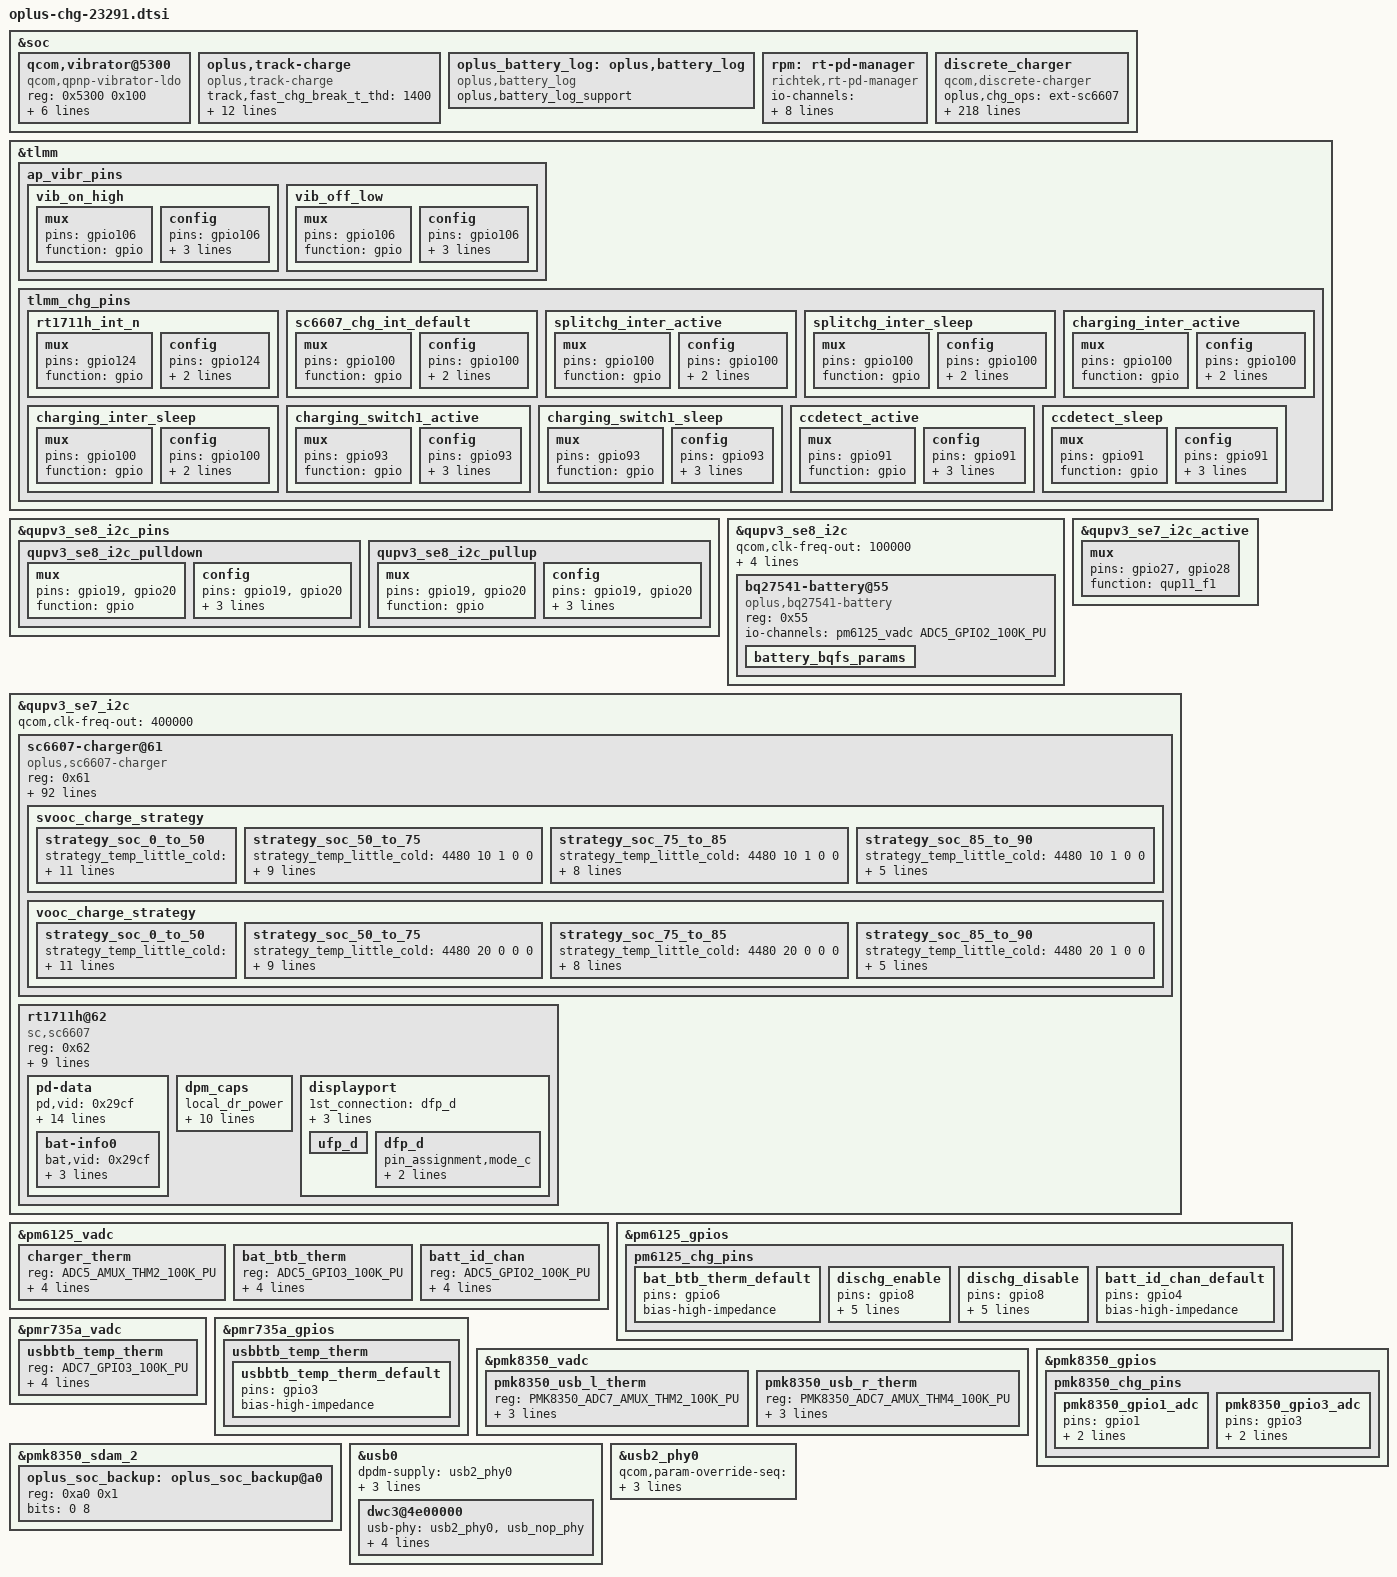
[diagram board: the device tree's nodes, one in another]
#include <dt-bindings/spmi/spmi.h>
#include <dt-bindings/iio/qcom,spmi-vadc.h>
#include <dt-bindings/iio/qti_power_supply_iio.h>

&soc {
	qcom,vibrator@5300 {
		compatible = "qcom,qpnp-vibrator-ldo";
		reg = <0x5300 0x100>;
		qcom,vib-ldo-volt-uv = <3000000>;
		qcom,disable-overdrive;
		qcom,vib-type = <1>;	/*0:ldo 1:gpio*/
		status = "okay";

		qcom,vibrator_switch-gpio = <&tlmm 106 0x00>;
		pinctrl-names = "vib_on_high", "vib_off_low";
		pinctrl-0 = <&vib_on_high>;
		pinctrl-1 = <&vib_off_low >;
	};

	oplus,track-charge {
		compatible = "oplus,track-charge";
		track,fast_chg_break_t_thd = <1400>;
		track,general_chg_break_t_thd = <200>;
		track,voocphy_type = <3>;
		track,wired_max_power = <67000>;
		track,wired_fast_chg_scheme = <2>;
		track,wls_max_power = <0>;
		track,wls_bpp_chg_scheme = <0>;
		track,wls_epp_chg_scheme = <0>;
		track,wls_fast_chg_scheme = <0>;
		track,nominal_qmax1 = <4824>;
		track,nominal_fcc = <4510>;
		track,gauge_status_ctrl;
		track,external_gauge_num = <1>;
	};

	oplus_battery_log: oplus,battery_log {
		compatible = "oplus,battery_log";
		oplus,battery_log_support;
	};
};

&tlmm {
	ap_vibr_pins {
		vib_on_high {
			mux {
				pins = "gpio106";
				function = "gpio";
			};

			config {
				pins = "gpio106";
				drive-strength = <2>;
				bias-disable;
				output-high;
			};
		};

		vib_off_low {
			mux {
				pins = "gpio106";
				function = "gpio";
			};

			config {
				pins = "gpio106";
				drive-strength = <2>;
				bias-disable;
				output-low;
			};
		};
	};
};

&qupv3_se8_i2c_pins {
	qupv3_se8_i2c_pulldown: qupv3_se8_i2c_pulldown {
		mux {
			pins = "gpio19", "gpio20";
			function = "gpio";
		};

		config {
			pins = "gpio19", "gpio20";
			drive-strength = <2>;
			bias-pull-down;
			output-low;
		};
	};

	qupv3_se8_i2c_pullup: qupv3_se8_i2c_pullup {
		mux {
			pins = "gpio19", "gpio20";
			function = "gpio";
		};

		config {
			pins = "gpio19", "gpio20";
			drive-strength = <2>;
			bias-pull-up;
			input-enable;
		};
	};
};

&qupv3_se8_i2c {
	status = "okay";
	qcom,clk-freq-out = <100000>;
	pinctrl-names = "default", "sleep", "pulldown", "pullup";
	pinctrl-0 = <&qupv3_se8_i2c_active>;
	pinctrl-1 = <&qupv3_se8_i2c_sleep>;
	pinctrl-2 = <&qupv3_se8_i2c_pulldown>;
	pinctrl-3 = <&qupv3_se8_i2c_pullup>;

	bq27541-battery@55 {
		status = "okay";
		compatible = "oplus,bq27541-battery";
		reg = <0x55>;
		io-channels = <&pm6125_vadc ADC5_GPIO2_100K_PU>;
		io-channel-names = "batt_id_chan";
		battery_bqfs_params {
			#include "oplus-bqfs-23091.dtsi"
		};
	};

};

&soc {
	rpm: rt-pd-manager {
		compatible = "richtek,rt-pd-manager";
		#io-channel-cells = <1>;
		io-channels = <&discrete_charger PSY_IIO_PD_ACTIVE>,
			      <&discrete_charger PSY_IIO_PD_USB_SUSPEND_SUPPORTED>,
			      <&discrete_charger PSY_IIO_PD_IN_HARD_RESET>,
			      <&discrete_charger PSY_IIO_PD_CURRENT_MAX>,
			      <&discrete_charger PSY_IIO_PD_VOLTAGE_MIN>,
			      <&discrete_charger PSY_IIO_PD_VOLTAGE_MAX>,
			      <&discrete_charger PSY_IIO_USB_REAL_TYPE>,
			      <&discrete_charger PSY_IIO_PD_SDP>;
		io-channel-names = "pd_active",
				   "pd_usb_suspend_supported",
				   "pd_in_hard_reset",
				   "pd_current_max",
				   "pd_voltage_min",
				   "pd_voltage_max",
				   "real_type",
				   "pd_sdp";
	};
};

&qupv3_se7_i2c_active {
	mux {
		pins = "gpio27", "gpio28";
		function = "qup11_f1";
	};
};

/*#ifdef OPLUS_FEATURE_CHG_BASIC*/
&qupv3_se7_i2c {
	status = "okay";
	qcom,clk-freq-out = <400000>;
	sc6607-charger@61 {
		status = "okay";
		compatible = "oplus,sc6607-charger";
		reg = <0x61>; /*The device operates as a slave device with address 75H*/

		qcom,chg_irq_gpio = <&tlmm 100 0x00>;
		dpdm-supply = <&usb2_phy0>;
		pinctrl-names = "default",
					"splitchg_inter_active",
					"splitchg_inter_sleep";

		pinctrl-0 = <&sc6607_chg_int_default>;
		pinctrl-1 = <&splitchg_inter_active>;
		pinctrl-2 = <&splitchg_inter_sleep>;

		sc,vsys-limit = <3400>;
		sc,vbat = <4450>;
		sc,charge-curr = <2000>;
		sc,iindpm-disable = <0>;
		sc,input-curr-limit = <500>;
		sc,ico-enable = <0>;
		sc,precharge-volt = <0>;      /* 0:2700mv , 1:3000mv */
		sc,precharge-curr = <500>;
		sc,term-en = <1>;
		sc,term-curr = <100>;     /* ma */
		sc,rechg-dis = <1>;
		sc,boost-voltage = <5000>;
		sc,boost-max-current = <1500>;
		sc,conv-ocp-dis = <0>;
		sc,tsbat-jeita-dis = <1>;
		sc,vpmid-ovp-otg-dis = <0>;
		sc,vbat-ovp-buck-dis = <0>;
		sc,ibat-ocp = <1>;    /* 0:12A , 1:16A */
		sc,charge-detect-enable;
		sc,disable-qc;
		qcom,copycat_vooc_support;
		oplus,copycat_identify_algorithm = <2>;
		oplus,copycat-vooc-count = <4>;

		/*
		 * Charger name
		 * Main charger: primary_chg
		 * Slave charger: secondary_chg
		 */
		charger_name = "primary_chg";

		qcom,mb_gauge_support;
		qcom,charging_switch1-gpio = <&tlmm 93 0x00>;

		ovp_reg = <0x36>;   /* 4850mv*/
		ocp_reg = <0xf>;    /* 4750mA*/

		qcom,voocphy_current_default = <41>;/*4100mA*/

		qcom,svooc_cool_down_current_limit = <82 20 20 24 30 34 40 44 50 54 82>;
		qcom,vooc_cool_down_current_limit = <30 20 20 24 30>;
		qcom,abnormal_adapter_current = <60 60 40 40>;
		qcom,vooc_little_cold_full_voltage = <4470>;
		qcom,vooc_cool_full_voltage = <4480>;
		qcom,vooc_warm_full_voltage = <4130>;
		qcom,vooc_1time_full_voltage = <4530>;
		qcom,vooc_ntime_full_voltage = <4520>;
		qcom,low_curr_full_t1 = <120>;
		qcom,low_curr_full_t2 = <350>;
		qcom,low_curr_full_t3 = <430>;
		qcom,range1_low_curr_full =	<850 4520
						  750 4515
						  650 4500
						  550 4490
						  450 4480>;
		qcom,range2_low_curr_full =	<900 4520
						 800 4515
						 700 4500
						 600 4490
						 500 4480>;

		qcom,vooc_multistep_initial_batt_temp = <1000>;
		qcom,vooc_little_cool_temp = <200>;
		qcom,vooc_cool_temp = <120>;
		qcom,vooc_little_cold_temp = <50>;
		qcom,vooc_normal_low_temp = <350>;
		qcom,vooc_strategy_normal_current = <100>;
		qcom,vooc_normal_to_little_cool_current = <100>;
		qcom,vooc_batt_over_high_temp = <510>;
		qcom,vooc-low-temp = <0>;
		qcom,vooc-high-temp = <500>;
		qcom,vooc-low-soc = <0>;
		qcom,vooc-high-soc = <90>;
		qcom,vooc-normal-high-temp = <430>;
		qcom,vooc-warm-allow-vol = <4000>;
		qcom,vooc-warm-allow-soc = <50>;

		qcom,vooc_strategy1_batt_high_temp0 = <385>;
		qcom,vooc_strategy1_batt_high_temp1 = <395>;
		qcom,vooc_strategy1_batt_high_temp2 = <420>;
		qcom,vooc_strategy1_batt_low_temp2 = <410>;
		qcom,vooc_strategy1_batt_low_temp1 = <385>;
		qcom,vooc_strategy1_batt_low_temp0 = <375>;

		qcom,vooc_strategy1_high_current0 = <80>;
		qcom,vooc_strategy1_high_current1 = <60>;
		qcom,vooc_strategy1_high_current2 = <40>;
		qcom,vooc_strategy1_low_current2 = <60>;
		qcom,vooc_strategy1_low_current1 = <80>;
		qcom,vooc_strategy1_low_current0 = <80>;

		qcom,vooc_strategy1_high_current0_vooc = <30>;
		qcom,vooc_strategy1_high_current1_vooc = <30>;
		qcom,vooc_strategy1_high_current2_vooc = <30>;
		qcom,vooc_strategy1_low_current2_vooc = <30>;
		qcom,vooc_strategy1_low_current1_vooc = <30>;
		qcom,vooc_strategy1_low_current0_vooc = <30>;

		qcom,voocphy_ibat_over_current = <8500>;
		qcom,voocphy_cp_max_ibus = <4750>;
		qcom,voocphy_svooc_cp_max_ibus = <4750>;
		qcom,voocphy_vooc_cp_max_ibus = <3500>;

		svooc_batt_sys_curve =	<0 1 0 1 0 0 1	// 4000mA
					 0 0 0 0 0 0 1	// 4604mV
					 0 0 1 0 1 0 0	// 2600mA
					 1 1 1 1 1 1 0	// 4604mV
					 0 0 0 1 0 1 0	// 1100mA
					 1 1 1 1 1 1 0>; // 4604mV

		vooc_batt_sys_curve =	<0 0 1 1 1 1 0	// 4000mA
					 0 0 0 0 0 0 1	// 4604mV
					 0 0 1 0 1 0 0	// 2600mA
					 1 1 1 1 1 1 0	// 4604mV
					 0 0 0 1 0 1 0	// 1100mA
					 1 1 1 1 1 1 0>; // 4604mV

	        svooc_charge_strategy {
	            strategy_soc_0_to_50 {
	                strategy_temp_little_cold =    <4150 15 0 0 0
	                                                4470 11 0 0 0
	                                                4480 10 1 0 0>;
	                strategy_temp_cool =           <4150 23 0 0 0
	                                                4150 20 0 0 0
	                                                4470 16 0 0 0
	                                                4470 15 0 0 0
	                                                4480 10 1 0 0>;
	                strategy_temp_little_cool =    <4150 35 0 0 0
	                                                4150 30 0 0 0
	                                                4480 28 0 0 0
	                                                4480 25 0 0 0
	                                                4480 20 0 0 0
	                                                4510 18 0 0 0
	                                                4510 15 0 0 0
	                                                4520 10 1 0 0>;
	                strategy_temp_normal_low =     <4230 41 0 0 0
	                                                4230 40 0 0 0
	                                                4230 35 0 0 0
	                                                4230 30 0 0 0
	                                                4480 28 0 0 0
	                                                4480 25 0 0 0
	                                                4480 20 0 0 0
	                                                4510 18 0 0 0
							4510 15 0 0 0
	                                                4520 10 1 0 0>;
	                strategy_temp_normal_high =    <4230 41 0 0 0
							4230 40 0 0 0
							4230 35 0 0 0
							4230 30 0 0 0
							4480 28 0 0 0
							4480 25 0 0 0
							4480 20 0 0 0
							4510 18 0 0 0
							4510 15 0 0 0
							4520 10 1 0 0>;
	                strategy_temp_warm =           <4120 13 0 0 0
							4130 10 1 0 0>;
	            };

	            strategy_soc_50_to_75 {
	                strategy_temp_little_cold =    <4480 10 1 0 0>;
	                strategy_temp_cool =           <4470 15 0 0 0
	                                                4480 10 1 0 0>;
	                strategy_temp_little_cool =    <4480 20 0 0 0
	                                                4510 18 0 0 0
							4510 15 0 0 0
	                                                4520 10 1 0 0>;
	                strategy_temp_normal_low =     <4480 25 0 0 0
	                                                4480 20 0 0 0
							4510 18 0 0 0
							4510 15 0 0 0
	                                                4520 10 1 0 0>;
	                strategy_temp_normal_high =    <4480 25 0 0 0
							4480 20 0 0 0
							4510 18 0 0 0
							4510 15 0 0 0
	                                                4520 10 1 0 0>;
	                strategy_temp_warm =           <4130 10 1 0 0>;
	            };

	            strategy_soc_75_to_85 {
	                strategy_temp_little_cold =    <4480 10 1 0 0>;
	                strategy_temp_cool =           <4480 20 0 0 0>;
	                strategy_temp_little_cool =    <4510 15 0 0 0
	                                                4520 10 1 0 0>;
	                strategy_temp_normal_low =     <4510 15 0 0 0
	                                                4520 10 1 0 0>;
	                strategy_temp_normal_high =    <4510 15 0 0 0
	                                                4520 10 1 0 0>;
	                strategy_temp_warm =           <4130 10 1 0 0>;
	            };

	            strategy_soc_85_to_90 {
	                strategy_temp_little_cold =    <4480 10 1 0 0>;
	                strategy_temp_cool =           <4480 10 1 0 0>;
	                strategy_temp_little_cool =    <4520 10 1 0 0>;
	                strategy_temp_normal_low =     <4520 10 1 0 0>;
	                strategy_temp_normal_high =    <4520 10 1 0 0>;
	                strategy_temp_warm =           <4130 10 1 0 0>;
	            };
	        };

	        vooc_charge_strategy {
	            strategy_soc_0_to_50 {
	                strategy_temp_little_cold =    <4150 30 0 0 0
	                                                4470 22 0 0 0
	                                                4480 20 1 0 0>;
	                strategy_temp_cool =           <4470 30 0 0 0
	                                                4480 20 1 0 0>;
	                strategy_temp_little_cool =    <4510 30 0 0 0
	                                                4520 20 1 0 0>;
	                strategy_temp_normal_low =     <4510 30 0 0 0
	                                                4520 20 1 0 0>;
	                strategy_temp_normal_high =    <4510 30 0 0 0
	                                                4520 20 1 0 0>;
	                strategy_temp_warm =           <4120 26 1 0 0
							4130 20 1 0 0>;
	            };

	            strategy_soc_50_to_75 {
	                strategy_temp_little_cold =    <4480 20 0 0 0>;
	                strategy_temp_cool =           <4470 30 0 0 0
	                                                4480 20 1 0 0>;
	                strategy_temp_little_cool =    <4510 30 0 0 0
	                                                4520 20 1 0 0>;
	                strategy_temp_normal_low =     <4510 30 0 0 0
	                                                4520 20 1 0 0>;
	                strategy_temp_normal_high =    <4510 30 0 0 0
	                                                4520 20 1 0 0>;
	                strategy_temp_warm =           <4130 20 1 0 0>;
	            };

	            strategy_soc_75_to_85 {
	                strategy_temp_little_cold =    <4480 20 0 0 0>;
	                strategy_temp_cool =           <4480 20 0 0 0>;
	                strategy_temp_little_cool =    <4510 30 0 0 0
	                                                4520 20 1 0 0>;
	                strategy_temp_normal_low =     <4510 30 0 0 0
	                                                4520 20 1 0 0>;
	                strategy_temp_normal_high =    <4510 30 0 0 0
	                                                4520 20 1 0 0>;
	                strategy_temp_warm =           <4130 20 1 0 0>;
	            };

	            strategy_soc_85_to_90 {
	                strategy_temp_little_cold =    <4480 20 1 0 0>;
	                strategy_temp_cool =           <4480 20 1 0 0>;
	                strategy_temp_little_cool =    <4520 20 1 0 0>;
	                strategy_temp_normal_low =     <4520 20 1 0 0>;
	                strategy_temp_normal_high =    <4520 20 1 0 0>;
	                strategy_temp_warm =           <4130 20 1 0 0>;
	            };
	        };
	};


	rt1711h@62 {
		compatible = "sc,sc6607";
		reg = <0x62>;
		status = "okay";
		tcpc-dual,supported_modes = <0>; /* 0: dfp/ufp, */
						 /* 1: dfp, 2: ufp */
		rt-tcpc,name = "type_c_port0"; /* tcpc_device's name */
		rt-tcpc,role_def = <1>; /* 0: Unknown, 1: SNK, 2: SRC */
					/* 3: DRP, 4: Try.SRC, 5: Try.SNK */
		rt-tcpc,rp_level = <0>; /* 0: Default, 1: 1.5, 2: 3.0 */
		rt-tcpc,vconn_supply  = <1>;  /* 0: Never, 1: Always, */
					      /* 2: EMarkOnly, 3: StartOnly */
		/* rt-tcpc,disable_pe; */
		rt1711pd,intr_gpio = <&tlmm 124 0x0>;
		rt1711pd,intr_gpio_num = <124>;
		rt,disable_irq_reset;
		pinctrl-names = "default";
		pinctrl-0 = <&rt1711h_int_n>;
		pd-data {
			pd,vid = <0x29cf>;
			pd,pid = <0x1711>;
			pd,source-cap-ext = <0x171129cf 0x00000000 0x00000000
					     0x00000000 0x00000000 0x02000000>;
			pd,mfrs = "RichtekTCPC";

			/*
			 *	VSAFE5V = 0, MAX_POWER = 1, CUSTOM = 2,
			 *	MAX_POWER_LV = 0x21, MAX_POWER_LVIC = 0x31
			 *	MAX_POWER_HV = 0x41, MAX_POWER_HVIC = 0x51
			 */
			pd,charging_policy= <0x31>;

			/*
			 * Fixed 5V, 500 mA <0x00019032>
			 * Fixed 5V, 1A <0x00019064>
			 * Fixed 5V, 2A <0x000190c8>
			 * Fixed 5V, 3A <0x0001912c>
			 * Fixed 9V, 500 mA <0x0002d032>
			 * Fixed 9V, 1A <0x0002d064>
			 * Fixed 9V, 2A <0x0002d0c8>
			 * Fixed 9V, 3A <0x0002d12c>
			 * Variable 5-9V, 1A <0x8642d064>
			 * Variable 5-9V, 2A <0x8642d0c8>
			 * Variable 5-9V, 3A <0x8642d12c>
			 * PPS 3V~5.9V, 3A <0xC0761E3C>
			 */
			pd,source-pdo-size = <1>;
			pd,source-pdo-data = <0x00019032>;
			pd,sink-pdo-size = <1>;
			pd,sink-pdo-data = <0x000190c8>;

			/*
			 * No DP, host + device
			 *	pd,id-vdo-size = <6>;
			 *	pd,id-vdo-data = <0xd14029cf 0x0 0x17110000
						  0x41800000 0x0 0x21800000>;
			 * With DP
			 *	pd,id-vdo-size = <6>;
			 *	pd,id-vdo-data = <0xd54029cf 0x0 0x17110000
						  0x41800000 0x0 0x21800000>;
			 */

			pd,id-vdo-size = <6>;
			pd,id-vdo-data = <0xd14029cf 0x0 0x17110000
					  0x41800000 0x0 0x21800000>;

			bat,nr = <1>;
			pd,country_nr = <0>;

			bat-info0 {
				bat,vid = <0x29cf>;
				bat,pid = <0x1711>;
				bat,mfrs = "bat1";
				bat,design_cap = <17>;
			};

			//bat-info1 {
			//	bat,vid = <0x8abc>;
			//	bat,pid = <0x5234>;
			//	bat,mfrs = "bat2";
			//	bat,design_cap = <4000>;
			//};

			//country0 {
			//	pd,country_code = <0x5457>;
			//	pd,country_len = <2>; /* max len = 26 */
			//	pd,country_data = <0xff 0xff>;
			//};

			//country1 {
			//	pd,country_code = <0x5553>;
			//	pd,country_len = <3>; /* max len = 26 */
			//	pd,country_data = <0xf1 0xf2 0xf3>;
			//};
		};
		dpm_caps {
			local_dr_power;
			local_dr_data;
			//local_ext_power;
			local_usb_comm;
			//local_usb_suspend;
			//local_high_cap;
			//local_give_back;
			local_no_suspend;
			local_vconn_supply;

			//attemp_discover_cable_dfp;
			attemp_enter_dp_mode;
			attemp_discover_cable;
			attemp_discover_id;
			attemp_discover_svid;

			/* 0: disable, 1: prefer_snk, 2: prefer_src */
			pr_check = <0>;
			//pr_reject_as_source;
			//pr_reject_as_sink;
			//pr_check_gp_source;
			//pr_check_gp_sink;

			/* 0: disable, 1: prefer_ufp, 2: prefer_dfp */
			dr_check = <0>;
			//dr_reject_as_dfp;
			//dr_reject_as_ufp;
		};
		displayport {
			/* connection type = "both", "ufp_d", "dfp_d" */
			1st_connection = "dfp_d";
			2nd_connection = "dfp_d";
			signal,dp_v13;
			//signal,dp_gen2;
			//usbr20_not_used;
			typec,receptacle;
			ufp_d {
				//pin_assignment,mode_a;
				//pin_assignment,mode_b;
				//pin_assignment,mode_c;
				//pin_assignment,mode_d;
				//pin_assignment,mode_e;
			};
			dfp_d {
				//pin_assignment,mode_a;
				//pin_assignment,mode_b;
				pin_assignment,mode_c;
				pin_assignment,mode_d;
				pin_assignment,mode_e;
				//pin_assignment,mode_f;
			};
		};
	};
};

&tlmm {
	tlmm_chg_pins: tlmm_chg_pins {
		rt1711h_int_n: rt1711h_int_n {
			mux {
				pins = "gpio124";
				function = "gpio";
			};

			config {
				pins = "gpio124";
				drive-strength = <2>;
				bias-disable;
			};
		};

		sc6607_chg_int_default: sc6607_chg_int_default {
			mux {
				pins = "gpio100";
				function = "gpio";
			};

			config {
				pins = "gpio100";
				drive-strength = <2>;
				bias-disable;
			};
		};
		/*split_chg*/
		splitchg_inter_active: splitchg_inter_active {
			mux {
				pins = "gpio100";
				function = "gpio";
			};
			config {
				pins = "gpio100";
				drive-strength = <2>;
				bias-pull-up;
			};
		};

		splitchg_inter_sleep: splitchg_inter_sleep {
			mux {
				pins = "gpio100";
				function = "gpio";
			};
			config {
				pins = "gpio100";
				drive-strength = <2>;
				bias-pull-up;
			};
		};

		charging_inter_active: charging_inter_active {
			mux {
				pins = "gpio100";
				function = "gpio";
			};

			config {
				pins = "gpio100";
				drive-strength = <2>;
				bias-disable; /* NO PULL */
			};
		};

		charging_inter_sleep: charging_inter_sleep {
			mux {
				pins = "gpio100";
				function = "gpio";
			};

			config {
				pins = "gpio100";
				drive-strength = <2>;
				bias-disable; /* NO PULL */
			};
		};

		charging_switch1_active: charging_switch1_active {
			mux {
				pins = "gpio93";
				function = "gpio";
			};

			config {
				pins = "gpio93";
				drive-strength = <2>;
				bias-disable;
				output-high;
			};
		};

		charging_switch1_sleep: charging_switch1_sleep {
			mux {
				pins = "gpio93";
				function = "gpio";
			};

			config {
				pins = "gpio93";
				drive-strength = <2>;
				bias-disable;
				output-low;
			};
		};

		ccdetect_active: ccdetect_active {
			mux {
				pins = "gpio91";
				function = "gpio";
			};

			config {
				pins = "gpio91";
				drive-strength = <2>;
				input-enable;
				//bias-pull-up; /*PULL UP*/
				bias-disable;
			};
		};

		ccdetect_sleep: ccdetect_sleep {
			mux {
				pins = "gpio91";
				function = "gpio";
			};

			config {
				pins = "gpio91";
				drive-strength = <2>;
				//output-low;
				//bias-pull-down; /*PULL DOWN*/
				input-enable;
				bias-disable;
			};
		};
	};
};

&pm6125_vadc {
	charger_therm {
		reg = <ADC5_AMUX_THM2_100K_PU>;
		label = "charger_therm";
		qcom,ratiometric;
		qcom,hw-settle-time = <200>;
		qcom,pre-scaling = <1 1>;
	};

	bat_btb_therm {
		reg = <ADC5_GPIO3_100K_PU>;
		label = "bat_btb_therm";
		qcom,ratiometric;
		qcom,hw-settle-time = <200>;
		qcom,pre-scaling = <1 1>;
	};

	batt_id_chan {
		reg = <ADC5_GPIO2_100K_PU>;
		label = "batt_id_chan";
		qcom,scale-fn-type = <ADC_SCALE_HW_CALIB_DEFAULT>;
		qcom,hw-settle-time = <200>;
		qcom,pre-scaling = <1 1>;
	};
};

&pm6125_gpios {
	pm6125_chg_pins: pm6125_chg_pins {
		bat_btb_therm_default: bat_btb_therm_default {
			pins = "gpio6";
			bias-high-impedance;
		};

		dischg_enable: dischg_enable {
			pins = "gpio8";
			function = "normal";
			bias-disable;
			power-source = <0>;
			output-high;
			qcom,drive-strength = <3>;
		};

		dischg_disable: dischg_disable {
			pins = "gpio8";
			function = "normal";
			bias-disable;
			power-source = <0>;
			output-low;
			qcom,drive-strength = <3>;
		};

		batt_id_chan_default: batt_id_chan_default {
			pins = "gpio4";
			bias-high-impedance;
		};
	};
};

&pmr735a_vadc {
	usbbtb_temp_therm {
		reg = <ADC7_GPIO3_100K_PU>;
		label = "usbbtb_temp_therm";
		qcom,ratiometric;
		qcom,hw-settle-time = <200>;
		qcom,pre-scaling = <1 1>;
    };
};


&pmr735a_gpios {
	usbbtb_temp_therm {
		usbbtb_temp_therm_default: usbbtb_temp_therm_default {
			pins = "gpio3";
			bias-high-impedance;
        };
    };
};

&pmk8350_vadc {
	pmk8350_usb_l_therm: pmk8350_usb_l_therm {
		reg = <PMK8350_ADC7_AMUX_THM2_100K_PU>;
		label = "pmk8350_usb_l_therm";
		qcom,pre-scaling = <1 1>;
		qcom,scale-fn-type = <ADC_SCALE_HW_CALIB_DEFAULT>;
	};

	pmk8350_usb_r_therm: pmk8350_usb_r_therm {
		reg = <PMK8350_ADC7_AMUX_THM4_100K_PU>;
		label = "pmk8350_usb_r_therm";
		qcom,pre-scaling = <1 1>;
		qcom,scale-fn-type = <ADC_SCALE_HW_CALIB_DEFAULT>;
	};
};

&pmk8350_gpios {
	pmk8350_chg_pins: pmk8350_chg_pins {
		pmk8350_gpio1_adc: pmk8350_gpio1_adc {
			pins = "gpio1"; /* GPIO 1 */
			function = "normal"; /* normal */
			bias-high-impedance; /* DISABLE GPIO1 for ADC*/
		};

		pmk8350_gpio3_adc: pmk8350_gpio3_adc {
			pins = "gpio3"; /* GPIO 3 */
			function = "normal"; /* normal */
			bias-high-impedance; /* DISABLE GPIO3 for ADC*/
		};
	};
};

&pmk8350_sdam_2 {
	oplus_soc_backup: oplus_soc_backup@a0 {
		reg = <0xa0 0x1>;
		bits = <0 8>;
	};
};

&soc {
	discrete_charger: discrete_charger {
		compatible = "qcom,discrete-charger";
		status = "okay";

		oplus,chg_ops = "ext-sc6607";
		#io-channel-cells = <1>;
		io-channels = <&pmk8350_vadc PMK8350_ADC7_AMUX_THM2_100K_PU>,
				      <&pmk8350_vadc PMK8350_ADC7_AMUX_THM4_100K_PU>,
				      <&pmr735a_vadc ADC7_GPIO3_100K_PU>,
				      <&pm6125_vadc ADC5_GPIO3_100K_PU>,
				      <&pm6125_vadc ADC5_GPIO2_100K_PU>;
		io-channel-names = "usbtemp_r_v_chan",
				   "usbtemp_l_v_chan",
				   "usbbtb_temp_chan",
				   "batbtb_temp_chan",
				   "batt_id_chan";

		nvmem-cell-names = "oplus_soc_backup";
		nvmem-cells = <&oplus_soc_backup>;

		pinctrl-names = "default",
				"dischg_enable", "dischg_disable",
				"2uart_active", "2uart_sleep",
				"ccdetect_active", "ccdetect_sleep";

		pinctrl-0 = <&bat_btb_therm_default
			     &usbbtb_temp_therm_default
			     &pmk8350_gpio1_adc
			     &pmk8350_gpio3_adc
                             &batt_id_chan_default>;
		pinctrl-1 = <&dischg_enable>;
		pinctrl-2 = <&dischg_disable>;
		pinctrl-3 = <&qupv3_se9_2uart_active>;
		pinctrl-4 = <&qupv3_se9_2uart_sleep>;
		pinctrl-5 = <&ccdetect_active>;
		pinctrl-6 = <&ccdetect_sleep>;

		qcom,input_current_charger_ma = <2000>;
		qcom,pd_input_current_charger_ma = <1500>;
		qcom,qc_input_current_charger_ma = <2000>;
		qcom,input_current_usb_ma = <500>;
		qcom,input_current_cdp_ma = <1500>;
		qcom,input_current_camera_ma = <1200>;
		qcom,input_current_calling_ma = <1500>;

		qcom,led_warm_bat_decidegc = <350>;
		qcom,led_high_bat_decidegc = <370>;
		qcom,input_current_led_ma = <1200>;
		qcom,input_current_led_ma_high = <1200>;
		qcom,input_current_led_ma_warm = <1500>;
		qcom,input_current_led_ma_normal = <2000>;

		qcom,vooc_temp_bat_normal_decidegc = <350>;
		qcom,vooc_temp_bat_warm_decidegc = <370>;
		qcom,vooc_temp_bat_hot_decidegc = <440>;
		qcom,input_current_vooc_led_ma_high = <1200>;
		qcom,input_current_vooc_led_ma_warm = <1800>;
		qcom,input_current_vooc_led_ma_normal = <3600>;
		qcom,input_current_vooc_ma_normal = <3600>;

		qcom,input_current_vooc_ma_warm = <3200>;

		qcom,input_current_vooc_ma_high = <2200>;

		qcom,charger_current_vooc_ma_normal = <1800>;

		qcom,iterm_disabled = <0>;
		qcom,iterm_ma = <285>;
		qcom,recharge-mv = <100>;
		qcom,batt_capacity_mah = <5000>;/*typical capacity*/

		qcom,removed_bat_decidegc = <390>;  /*<-39C*/

		qcom,cold_bat_decidegc = <100>;  /*-10C~0C*/
		qcom,temp_cold_vfloat_mv = <4470>;
		qcom,temp_cold_fastchg_current_ma_high = <750>;
		qcom,temp_cold_fastchg_current_ma_low = <960>;
		qcom,temp_cold_fastchg_current_ma = <720>;
		qcom,pd_temp_cold_fastchg_current_ma_high = <800>;
		qcom,pd_temp_cold_fastchg_current_ma_low = <600>;
		qcom,qc_temp_cold_fastchg_current_ma_high = <800>;
		qcom,qc_temp_cold_fastchg_current_ma_low = <600>;

		qcom,little_cold_bat_decidegc = <0>;    /*0C~5C*/
		qcom,temp_little_cold_vfloat_mv = <4470>;
		qcom,temp_little_cold_fastchg_current_ma_high = <2200>;
		qcom,temp_little_cold_fastchg_current_ma_low = <2000>;
		qcom,temp_little_cold_fastchg_current_ma = <2000>;
		qcom,pd_temp_little_cold_fastchg_current_ma_high = <3000>;
		qcom,pd_temp_little_cold_fastchg_current_ma_low = <2000>;
		qcom,qc_temp_little_cold_fastchg_current_ma_high = <3000>;
		qcom,qc_temp_little_cold_fastchg_current_ma_low = <2000>;

		qcom,cool_bat_decidegc = <50>;  /*5C~12C*/
		qcom,temp_cool_vfloat_mv = <4470>;
		qcom,temp_cool_fastchg_current_ma_high = <2200>;
		qcom,temp_cool_fastchg_current_ma_low = <2200>;
		qcom,pd_temp_cool_fastchg_current_ma_high = <3000>;
		qcom,pd_temp_cool_fastchg_current_ma_low = <3000>;
		qcom,qc_temp_cool_fastchg_current_ma_high = <3000>;
		qcom,qc_temp_cool_fastchg_current_ma_low = <3000>;

		qcom,little_cool_bat_decidegc = <120>;  /*12C~16C*/
		qcom,temp_little_cool_vfloat_mv = <4470>;
		qcom,temp_little_cool_fastchg_current_ma = <2200>;
		qcom,pd_temp_little_cool_fastchg_current_ma = <3000>;
		qcom,qc_temp_little_cool_fastchg_current_ma = <3000>;

		qcom,normal_bat_decidegc = <160>;       /*16C~45C*/
		qcom,temp_normal_vfloat_mv = <4470>;
		qcom,temp_normal_fastchg_current_ma = <2200>;
		qcom,pd_temp_normal_fastchg_current_ma = <3000>;
		qcom,qc_temp_normal_fastchg_current_ma = <3000>;

		qcom,warm_bat_decidegc = <450>;         /*45C~53C*/ /*8pin Bat Vooc project need add 3 degree C*/
		qcom,temp_warm_vfloat_mv = <4130>;
		qcom,temp_warm_fastchg_current_ma = <2200>;
		qcom,pd_temp_warm_fastchg_current_ma = <2200>;
		qcom,qc_temp_warm_fastchg_current_ma = <2200>;
		qcom,temp_warm_fastchg_current_ma_led_on = <1000>;

		qcom,hot_bat_decidegc = <530>;

		qcom,non_standard_vfloat_mv = <3980>;
		qcom,non_standard_fastchg_current_ma = <500>;

		qcom,short_c_bat_cv_mv = <4330>;
		qcom,short_c_bat_vfloat_mv = <3800>;
		qcom,short_c_bat_fastchg_current_ma = <512>;

		qcom,cold_vfloat_sw_limit = <4420>;
		qcom,little_cold_vfloat_sw_limit = <4420>;
		qcom,cool_vfloat_sw_limit = <4420>;
		qcom,little_cool_vfloat_sw_limit = <4420>;
		qcom,normal_vfloat_sw_limit = <4420>;
		qcom,warm_vfloat_sw_limit = <4080>;
		qcom,non_standard_vfloat_sw_limit = <3930>;
		qcom,short_c_bat_vfloat_sw_limit = <3750>;

		qcom,max_chg_time_sec = <64800>;
		qcom,charger_hv_thr = <10000>;
		qcom,charger_recv_thr = <9800>;
		qcom,charger_lv_thr = <3400>;
		qcom,vbatt_full_thr = <4435>;
		qcom,vbatt_hv_thr = <4600>;

		qcom,vfloat_step_mv = <8>;
		qcom,cold_vfloat_over_sw_limit = <4480>;
		qcom,little_cold_vfloat_over_sw_limit = <4480>;
		qcom,cool_vfloat_over_sw_limit = <4480>;
		qcom,little_cool_vfloat_over_sw_limit = <4480>;
		qcom,normal_vfloat_over_sw_limit = <4480>;
		qcom,warm_vfloat_over_sw_limit = <4140>;
		qcom,non_standard_vfloat_over_sw_limit = <3990>;

		qcom,vbatt_power_off = <3300>;
		qcom,vbatt_soc_1 = <3410>;
		qcom,vooc_project = <21>; /* 45w */
		qcom,vbatt_num = <1>;
		qcom,new_ui_warning_support;
		qcom,voocphy_support = <2>; /* AP_SINGLE_CP_VOOCPHY */
		//qcom,chargerid_support;
		qcom,external_gauge;
		qcom,ffc_support;
		qcom,dual_ffc;
		qcom,smart_charging_screenoff;
		qcom,vooc_show_ui_soc_decimal;
		qcom,ui_soc_decimal_speedmin = <20>;//2A
		oplus,boot_reset_adapter;
		qcom,check_batt_full_by_sw;
		qcom,chg_ctrl_by_lcd;
		qcom,chg_ctrl_by_camera;
		qcom,chg_ctrl_by_calling;

		qcom,sw_vfloat_over_protect_enable;

		qcom,normal_vterm_hw_inc = <18>;
		qcom,non_normal_vterm_hw_inc = <18>;
		qcom,usbtemp_batttemp_gap = <12>;

		qcom,ff1_normal_fastchg_ma = <1300>;
		qcom,ff1_warm_fastchg_ma = <1300>;

		qcom,ffc2_normal_fastchg_ma = <800>;/*16C~35c*/
		qcom,ffc2_warm_fastchg_ma = <850>;/*35C~40c*/
		qcom,ffc2_temp_low_decidegc = <120>;
		qcom,ffc2_temp_warm_decidegc = <350>;
		qcom,ffc2_temp_high_decidegc = <400>;

		qcom,ff1_exit_step_ma = <150>;
		qcom,ff1_warm_exit_step_ma = <150>;
		qcom,ffc2_exit_step_ma = <150>;
		qcom,ffc2_warm_exit_step_ma = <150>;

		qcom,ffc_normal_vfloat_sw_limit = <4515>;
		qcom,ffc_temp_normal_vfloat_mv = <4590>;
		qcom,ffc_normal_vfloat_over_sw_limit = <4590>;
		qcom,ffc_warm_vfloat_sw_limit = <4515>;

		qcom,ffc2_normal_vfloat_sw_limit = <4515>;
		qcom,ffc2_temp_normal_vfloat_mv = <4590>;
		qcom,ffc2_normal_vfloat_over_sw_limit = <4590>;
		qcom,ffc2_warm_vfloat_sw_limit = <4515>;

		full_pre_ffc_judge;
		full-pre-ffc-mv = <4465>;

		qcom,default_iterm_ma = <285>;
		qcom,default_temp_normal_fastchg_current_ma = <2200>;
		qcom,default_normal_vfloat_sw_limit = <4420>;
		qcom,default_temp_normal_vfloat_mv = <4470>;
		qcom,default_normal_vfloat_over_sw_limit = <4480>;

		qcom,default_temp_little_cool_fastchg_current_ma = <2200>;
		qcom,default_little_cool_vfloat_sw_limit = <4420>;
		qcom,default_temp_little_cool_vfloat_mv = <4470>;
		qcom,default_little_cool_vfloat_over_sw_limit = <4480>;

		oplus,uart_tx-gpio = <&tlmm 26 0x00>;
		oplus,uart_rx-gpio = <&tlmm 25 0x00>;

		//for PD9V or QC9V
		qcom,vbatt_pdqc_to_5v_thr = <4500>;
		qcom,vbatt_pdqc_to_9v_thr = <4500>;

		//GPIO config:
		//qcom,chargerid_switch-gpio = <&tlmm 50 0x00>;
		qcom,dischg-gpio = <&pm6125_gpios 8 0x00>;

		qcom,vooc-max-input-volt-support = <11000>;     //11V
		qcom,vooc-max-input-current-support = <4100>;   //4.1A
		qcom,ccdetect-gpio = <&tlmm 91 0x00>;
		qcom,use_vooc_charging_animation;
		qcom,support_usbtemp_protect_v2;
		qcom,usbtemp_batt_temp_low = <50>;
		qcom,usbtemp_batt_temp_high = <50>;
		qcom,usbtemp_ntc_temp_low = <57>;
		qcom,usbtemp_ntc_temp_high = <69>;
		qcom,usbtemp_temp_gap_low_with_batt_temp = <7>;
		qcom,usbtemp_temp_gap_high_with_batt_temp = <12>;
		qcom,usbtemp_temp_gap_low_without_batt_temp = <12>;
		qcom,usbtemp_temp_gap_high_without_batt_temp = <24>;
		qcom,usbtemp_rise_fast_temp_low = <3>;
		qcom,usbtemp_rise_fast_temp_high = <3>;
		qcom,usbtemp_rise_fast_temp_count_low = <30>;
		qcom,usbtemp_rise_fast_temp_count_high = <20>;

		qcom,usbtemp_cool_down_ntc_low = <54>;
		qcom,usbtemp_cool_down_ntc_high = <65>;
		qcom,usbtemp_cool_down_gap_low = <12>;
		qcom,usbtemp_cool_down_gap_high = <20>;
		qcom,usbtemp_cool_down_recover_ntc_low = <48>;
		qcom,usbtemp_cool_down_recover_ntc_high = <60>;
		qcom,usbtemp_cool_down_recover_gap_low = <6>;
		qcom,usbtemp_cool_down_recover_gap_high = <15>;
		oplus,smooth_switch_v2;
		oplus,reserve_chg_soc = <3>;
		oplus,reserve_dis_soc = <3>;
		qcom,support_abnormal_adapter;
		oplus,support_shipmode_in_chgic;
		oplus,not_support_usb_btb;
	};
};

&usb0 {
	dpdm-supply = <&usb2_phy0>;
	extcon = <&rpm>;
	#io-channel-cells = <1>;
	io-channels= <&discrete_charger PSY_IIO_USB_REAL_TYPE>;
	io-channel-names = "chg_type";
	dwc3@4e00000 {
		usb-phy = <&usb2_phy0>, <&usb_nop_phy>;
		maximum-speed = "high-speed";
		dr_mode = "otg";
		snps,usb2-lpm-disable;
		snps,usb2-gadget-lpm-disable;
	};
};

&usb2_phy0 {
	qcom,param-override-seq =
		<0x07 0x6c	/* override_x0 */
		 0xcc 0x70	/* override_x1 */
		 0x1b 0x74	/* override x2 */
		 0x03 0x78>;	/* override x3 */
	qcom,param-override-host-seq =
		<0xc7 0x6c	/* override_x0 */
		 0xc9 0x70	/* override_x1 */
		 0x14 0x74	/* override x2 */
		 0x03 0x78>;	/* override x3 */
};
